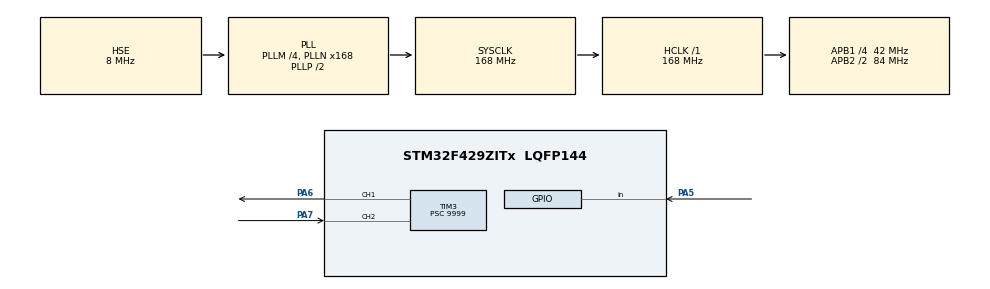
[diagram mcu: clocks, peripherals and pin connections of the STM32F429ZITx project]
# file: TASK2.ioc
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Mcu.Family=STM32F4
Mcu.Name=STM32F429ZITx
Mcu.Package=LQFP144
NVIC.PriorityGroup=NVIC_PRIORITYGROUP_4
NVIC.TIM3_IRQn=true\:0\:0\:false\:false\:true\:true\:true
PA5.Signal=GPIO_Input
PA6.Signal=S_TIM3_CH1
PA7.Signal=S_TIM3_CH2
PH0/OSC_IN.Mode=HSE-External-Oscillator
PH0/OSC_IN.Signal=RCC_OSC_IN
PH1/OSC_OUT.Mode=HSE-External-Oscillator
PH1/OSC_OUT.Signal=RCC_OSC_OUT
ProjectManager.HeapSize=0x200
ProjectManager.StackSize=0x400
ProjectManager.TargetToolchain=EWARM V8.32
RCC.48MHZClocksFreq_Value=84000000
RCC.AHBFreq_Value=168000000
RCC.APB1CLKDivider=RCC_HCLK_DIV4
RCC.APB1Freq_Value=42000000
RCC.APB1TimFreq_Value=84000000
RCC.APB2CLKDivider=RCC_HCLK_DIV2
RCC.APB2Freq_Value=84000000
RCC.APB2TimFreq_Value=168000000
RCC.CortexFreq_Value=168000000
RCC.HCLKFreq_Value=168000000
RCC.HSE_VALUE=8000000
RCC.HSI_VALUE=16000000
RCC.LSE_VALUE=32768
RCC.PLLM=4
RCC.PLLN=168
RCC.PLLSourceVirtual=RCC_PLLSOURCE_HSE
RCC.SYSCLKFreq_VALUE=168000000
RCC.SYSCLKSource=RCC_SYSCLKSOURCE_PLLCLK
RCC.VCOOutputFreq_Value=336000000
SH.S_TIM3_CH1.0=TIM3_CH1,PWM Generation1 CH1
SH.S_TIM3_CH2.0=TIM3_CH2,Input_Capture2_from_TI2
TIM3.Channel-Input_Capture2_from_TI2=TIM_CHANNEL_2
TIM3.Channel-PWM\ Generation1\ CH1=TIM_CHANNEL_1
TIM3.ICPolarity_CH2=TIM_INPUTCHANNELPOLARITY_BOTHEDGE
TIM3.Period=230
TIM3.Prescaler=9999
TIM3.Pulse-PWM\ Generation1\ CH1=40000
VP_TIM3_VS_ClockSourceINT.Mode=Internal
board=custom

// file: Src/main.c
/* USER CODE BEGIN Header */
/**
  ******************************************************************************
  * @file           : main.c
  * @brief          : Main program body
  ******************************************************************************
  * @attention
  *
  * <h2><center>&copy; Copyright (c) 2020 STMicroelectronics.
  * All rights reserved.</center></h2>
  *
  * This software component is licensed by ST under BSD 3-Clause license,
  * the "License"; You may not use this file except in compliance with the
  * License. You may obtain a copy of the License at:
  *                        opensource.org/licenses/BSD-3-Clause
  *
  ******************************************************************************
  */
/* USER CODE END Header */

#include "main.h"

TIM_HandleTypeDef htim3;

/* USER CODE BEGIN PV */
extern uint64_t input;
extern uint64_t input_inch;
//Task Two
volatile uint16_t t1 = 0;
volatile uint16_t t2 = 0;
volatile uint16_t t3 = 0;

/* USER CODE END PV */

void SystemClock_Config(void);
static void MX_GPIO_Init(void);
static void MX_TIM3_Init(void);
/* USER CODE BEGIN PFP */
void initDisplay(void);
void command(char);
void write(uint16_t);
void write_string(char*);
void clear(void);

/* USER CODE END PFP */

/* USER CODE BEGIN 0 */
void initDisplay(void) {

 HAL_GPIO_WritePin(GPIOG, GPIO_PIN_1, GPIO_PIN_RESET); //E = 0;
 HAL_Delay(100); //Wait >15 msec after power is applied
 command(0x30); //command 0x30 = Wake up
 HAL_Delay(30); //must wait 5ms, busy flag not available
 command(0x30); //command 0x30 = Wake up #2
 HAL_Delay(10); //must wait 160us, busy flag not available
 command(0x30); //command 0x30 = Wake up #3
 HAL_Delay(10); //must wait 160us, busy flag not available

 command(0x38); //Function set: 8-bit/2-line
 command(0x38); //Function set: 8-bit/2-line

 command(0x10); //cursor on
 command(0x0C); //cursor set
 command(0x01); //clear
 command(0x06); //Entry mode set
}

void command(char i) {

 HAL_GPIO_WritePin(GPIOG, GPIO_PIN_2, GPIO_PIN_RESET); //D/I=LOW : send instruction
 HAL_GPIO_WritePin(GPIOG, GPIO_PIN_3, GPIO_PIN_RESET); //R/W=LOW : Write
 GPIOD -> ODR = i; //put data on output Port
 HAL_GPIO_WritePin(GPIOG, GPIO_PIN_1, GPIO_PIN_SET); //E = 1;
 HAL_Delay(10); //enable pulse width >= 300ns
 HAL_GPIO_WritePin(GPIOG, GPIO_PIN_1, GPIO_PIN_RESET);  //Clock enable: falling edge
 HAL_Delay(10);
}

void write(uint16_t i) {

 HAL_GPIO_WritePin(GPIOG, GPIO_PIN_2, GPIO_PIN_SET); //D/I=HIGH : send data
 HAL_GPIO_WritePin(GPIOG, GPIO_PIN_3, GPIO_PIN_RESET); //R/W=LOW : Write

 GPIOD -> ODR = i; //put data on output Port

 HAL_GPIO_WritePin(GPIOG, GPIO_PIN_1, GPIO_PIN_SET); //E = 1;
 HAL_Delay(1); //enable pulse width >= 300ns
 HAL_GPIO_WritePin(GPIOG, GPIO_PIN_1, GPIO_PIN_RESET);  //Clock enable: falling edge
 HAL_Delay(2);
}

void write_string(char *display_string) {
  clear();
  uint8_t flag = 0;
  for(uint8_t i = 0; i < 16; i++){
    if(flag == 0){
      write(display_string[i]);
    }
    else {
      write(0x00);
    }
    if(display_string[i] == '\0'){
      flag = 1;
    }
  }
}

/* USER CODE END 0 */

int main(void)
{

  /* MCU Configuration--------------------------------------------------------*/

  /* Reset of all peripherals, Initializes the Flash interface and the Systick. */
  HAL_Init();

  /* Configure the system clock */
  SystemClock_Config();

  /* Initialize all configured peripherals */
  MX_GPIO_Init();
  MX_TIM3_Init();

  /* Infinite loop */
  /* USER CODE BEGIN WHILE */
  while (1)
  {
  int readValue = HAL_GPIO_ReadPin(GPIOA, GPIO_PIN_5);  // read status of the dip switch.
  if (readValue == 1) {                       // diaplay in inch
  t3 = (input_inch / 100) + 48;
  t2 = ((input_inch % 100) / 10) + 48;
  t1 = (((input_inch % 100) % 10)) + 48;
  }
  else {                                        // disply in cm
  t3 = (input / 100) + 48;
  t2 = ((input % 100) / 10) + 48;
  t1 = (((input % 100) % 10)) + 48;
  }
  write(t3);
  write(t2);
  write(t1);

  command(0x10); //move cursor left
  command(0x10); //move cursor left
  command(0x10); //move cursor left

    /* USER CODE END WHILE */

  }
}

void SystemClock_Config(void)
{
  RCC_OscInitTypeDef RCC_OscInitStruct = {0};
  RCC_ClkInitTypeDef RCC_ClkInitStruct = {0};

  /** Configure the main internal regulator output voltage
  */
  __HAL_RCC_PWR_CLK_ENABLE();
  __HAL_PWR_VOLTAGESCALING_CONFIG(PWR_REGULATOR_VOLTAGE_SCALE1);
  /** Initializes the CPU, AHB and APB busses clocks
  */
  RCC_OscInitStruct.OscillatorType = RCC_OSCILLATORTYPE_HSE;
  RCC_OscInitStruct.HSEState = RCC_HSE_ON;
  RCC_OscInitStruct.PLL.PLLState = RCC_PLL_ON;
  RCC_OscInitStruct.PLL.PLLSource = RCC_PLLSOURCE_HSE;
  RCC_OscInitStruct.PLL.PLLM = 4;
  RCC_OscInitStruct.PLL.PLLN = 168;
  RCC_OscInitStruct.PLL.PLLP = RCC_PLLP_DIV2;
  RCC_OscInitStruct.PLL.PLLQ = 4;
  if (HAL_RCC_OscConfig(&RCC_OscInitStruct) != HAL_OK)
  {
    Error_Handler();
  }
  /** Initializes the CPU, AHB and APB busses clocks
  */
  RCC_ClkInitStruct.ClockType = RCC_CLOCKTYPE_HCLK|RCC_CLOCKTYPE_SYSCLK
                              |RCC_CLOCKTYPE_PCLK1|RCC_CLOCKTYPE_PCLK2;
  RCC_ClkInitStruct.SYSCLKSource = RCC_SYSCLKSOURCE_PLLCLK;
  RCC_ClkInitStruct.AHBCLKDivider = RCC_SYSCLK_DIV1;
  RCC_ClkInitStruct.APB1CLKDivider = RCC_HCLK_DIV4;
  RCC_ClkInitStruct.APB2CLKDivider = RCC_HCLK_DIV2;

  if (HAL_RCC_ClockConfig(&RCC_ClkInitStruct, FLASH_LATENCY_5) != HAL_OK)
  {
    Error_Handler();
  }
}

static void MX_TIM3_Init(void)
{

  TIM_ClockConfigTypeDef sClockSourceConfig = {0};
  TIM_MasterConfigTypeDef sMasterConfig = {0};
  TIM_OC_InitTypeDef sConfigOC = {0};
  TIM_IC_InitTypeDef sConfigIC = {0};

  htim3.Instance = TIM3;
  htim3.Init.Prescaler = 9999;
  htim3.Init.CounterMode = TIM_COUNTERMODE_UP;
  htim3.Init.Period = 230;
  htim3.Init.ClockDivision = TIM_CLOCKDIVISION_DIV1;
  htim3.Init.AutoReloadPreload = TIM_AUTORELOAD_PRELOAD_DISABLE;
  if (HAL_TIM_Base_Init(&htim3) != HAL_OK)
  {
    Error_Handler();
  }
  sClockSourceConfig.ClockSource = TIM_CLOCKSOURCE_INTERNAL;
  if (HAL_TIM_ConfigClockSource(&htim3, &sClockSourceConfig) != HAL_OK)
  {
    Error_Handler();
  }
  if (HAL_TIM_PWM_Init(&htim3) != HAL_OK)
  {
    Error_Handler();
  }
  if (HAL_TIM_IC_Init(&htim3) != HAL_OK)
  {
    Error_Handler();
  }
  sMasterConfig.MasterOutputTrigger = TIM_TRGO_RESET;
  sMasterConfig.MasterSlaveMode = TIM_MASTERSLAVEMODE_DISABLE;
  if (HAL_TIMEx_MasterConfigSynchronization(&htim3, &sMasterConfig) != HAL_OK)
  {
    Error_Handler();
  }
  sConfigOC.OCMode = TIM_OCMODE_PWM1;
  sConfigOC.Pulse = 40000;
  sConfigOC.OCPolarity = TIM_OCPOLARITY_HIGH;
  sConfigOC.OCFastMode = TIM_OCFAST_DISABLE;
  if (HAL_TIM_PWM_ConfigChannel(&htim3, &sConfigOC, TIM_CHANNEL_1) != HAL_OK)
  {
    Error_Handler();
  }
  sConfigIC.ICPolarity = TIM_INPUTCHANNELPOLARITY_BOTHEDGE;
  sConfigIC.ICSelection = TIM_ICSELECTION_DIRECTTI;
  sConfigIC.ICPrescaler = TIM_ICPSC_DIV1;
  sConfigIC.ICFilter = 0;
  if (HAL_TIM_IC_ConfigChannel(&htim3, &sConfigIC, TIM_CHANNEL_2) != HAL_OK)
  {
    Error_Handler();
  }
  HAL_TIM_MspPostInit(&htim3);

}

static void MX_GPIO_Init(void)
{
  GPIO_InitTypeDef GPIO_InitStruct = {0};

  /* GPIO Ports Clock Enable */
  __HAL_RCC_GPIOH_CLK_ENABLE();
  __HAL_RCC_GPIOA_CLK_ENABLE();

  /*Configure GPIO pin : PA5 */
  GPIO_InitStruct.Pin = GPIO_PIN_5;
  GPIO_InitStruct.Mode = GPIO_MODE_INPUT;
  GPIO_InitStruct.Pull = GPIO_NOPULL;
  HAL_GPIO_Init(GPIOA, &GPIO_InitStruct);

}

void Error_Handler(void)
{
}

/************************ (C) COPYRIGHT STMicroelectronics *****END OF FILE****/
